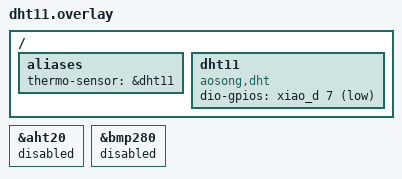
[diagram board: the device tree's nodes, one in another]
/*
 * 温湿度センサを DHT11 にする (XIAO ESP32C3. boards/xiao_esp32c3.overlay に足す)
 *
 * ビルド: THERMO_SENSOR=dht11 docker compose run --rm build-node
 * (west: -DEXTRA_DTC_OVERLAY_FILE=sensors/dht11.overlay -DEXTRA_CONF_FILE=sensors/dht11.conf)
 *
 * DHT11 (3 ピンのモジュール: + / out / -) を次のようにつなぐ.
 *   +   -> 3V3
 *   out -> D7 (GPIO20. 拡張ボードの, 下側のヘッダの RX'7)
 *   -   -> GND
 * dio-gpios は GPIO_ACTIVE_LOW にする (Zephyr のドライバが線が LOW の状態を active として扱うため).
 * D7 は起動時に, 信号が出ない (D6 は ROM のログが出る. D8 と D9 はストラッピングのピン).
 * DHT22 (AM2303) を使うときは dht11 のノードに, dht22; を足す.
 *
 * DHT11 は気圧を測れないので, alias thermo-pressure を消して, AHT20 と BMP280 を使わない.
 */
#include <zephyr/dt-bindings/gpio/gpio.h>

/ {
    aliases {
        thermo-sensor = &dht11;
        /delete-property/ thermo-pressure;
    };

    dht11: dht11 {
        compatible = "aosong,dht";
        status = "okay";
        /* ドライバは線を LOW にする状態を active として扱う (開始信号は LOW を 18 ms 出す).
         * GPIO_ACTIVE_HIGH にすると, 開始信号が HIGH になり, センサが応答せず, -EIO になる. */
        dio-gpios = <&xiao_d 7 (GPIO_PULL_UP | GPIO_ACTIVE_LOW)>;
    };
};

&aht20 {
    status = "disabled";
};

&bmp280 {
    status = "disabled";
};
